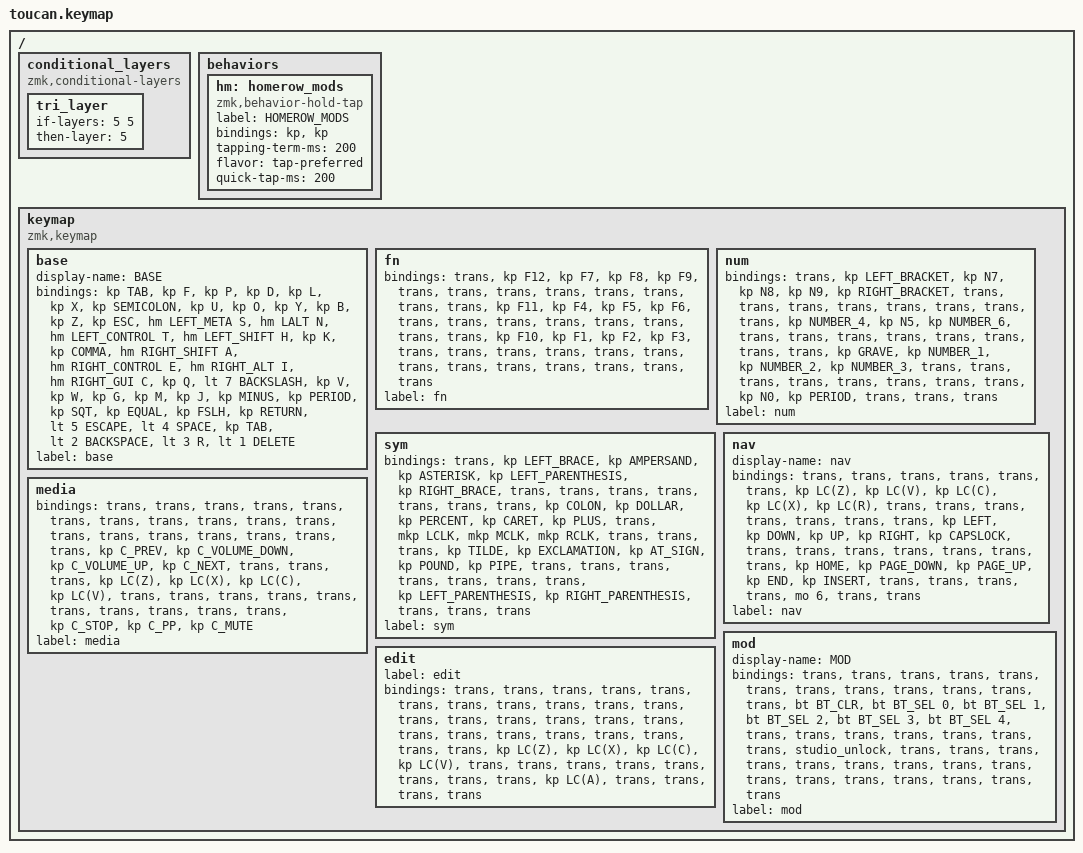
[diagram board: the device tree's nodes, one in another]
#include <behaviors.dtsi>
#include <dt-bindings/zmk/bt.h>
#include <dt-bindings/zmk/keys.h>
#include <dt-bindings/zmk/pointing.h>

#define BASE 0
#define NAV  1
#define SYM  2
#define ADJ  3

/ {
    conditional_layers {
        compatible = "zmk,conditional-layers";

        tri_layer {
            if-layers = <5 5>;
            then-layer = <5>;
        };
    };

    behaviors {
        hm: homerow_mods {
            compatible = "zmk,behavior-hold-tap";
            label = "HOMEROW_MODS";
            #binding-cells = <2>;
            bindings = <&kp>, <&kp>;

            tapping-term-ms = <200>;
            flavor = "tap-preferred";
            quick-tap-ms = <200>;
        };
    };

    keymap {
        compatible = "zmk,keymap";

        base {
            display-name = "BASE";
            bindings = <
&kp TAB  &kp F  &kp P  &kp D  &kp L  &kp X  &kp SEMICOLON  &kp U  &kp O  &kp Y  &kp B  &kp Z  &kp ESC  &hm LEFT_META S  &hm LALT N  &hm LEFT_CONTROL T  &hm LEFT_SHIFT H  &kp K  &kp COMMA  &hm RIGHT_SHIFT A  &hm RIGHT_CONTROL E  &hm RIGHT_ALT I  &hm RIGHT_GUI C  &kp Q  &lt 7 BACKSLASH  &kp V  &kp W  &kp G  &kp M  &kp J  &kp MINUS  &kp PERIOD  &kp SQT  &kp EQUAL  &kp FSLH  &kp RETURN  &lt 5 ESCAPE  &lt 4 SPACE  &kp TAB  &lt 2 BACKSPACE  &lt 3 R  &lt 1 DELETE
            >;

            label = "base";
        };

        fn {
            bindings = <
&trans  &kp F12  &kp F7  &kp F8  &kp F9  &trans  &trans  &trans  &trans  &trans  &trans  &trans  &trans  &kp F11  &kp F4  &kp F5  &kp F6  &trans  &trans  &trans  &trans  &trans  &trans  &trans  &trans  &kp F10  &kp F1  &kp F2  &kp F3  &trans  &trans  &trans  &trans  &trans  &trans  &trans  &trans  &trans  &trans  &trans  &trans  &trans
            >;

            label = "fn";
        };

        num {
            bindings = <
&trans  &kp LEFT_BRACKET  &kp N7  &kp N8  &kp N9  &kp RIGHT_BRACKET  &trans  &trans  &trans  &trans  &trans  &trans  &trans  &trans  &kp NUMBER_4  &kp N5  &kp NUMBER_6  &trans  &trans  &trans  &trans  &trans  &trans  &trans  &trans  &kp GRAVE  &kp NUMBER_1  &kp NUMBER_2  &kp NUMBER_3  &trans  &trans  &trans  &trans  &trans  &trans  &trans  &trans  &kp N0  &kp PERIOD  &trans  &trans  &trans
            >;

            label = "num";
        };

        sym {
            bindings = <
&trans  &kp LEFT_BRACE  &kp AMPERSAND  &kp ASTERISK  &kp LEFT_PARENTHESIS  &kp RIGHT_BRACE  &trans  &trans  &trans  &trans  &trans  &trans  &trans  &kp COLON  &kp DOLLAR  &kp PERCENT  &kp CARET  &kp PLUS  &trans  &mkp LCLK  &mkp MCLK  &mkp RCLK  &trans  &trans  &trans  &kp TILDE  &kp EXCLAMATION  &kp AT_SIGN  &kp POUND  &kp PIPE  &trans  &trans  &trans  &trans  &trans  &trans  &trans  &kp LEFT_PARENTHESIS  &kp RIGHT_PARENTHESIS  &trans  &trans  &trans
            >;

            label = "sym";
        };

        nav {
            display-name = "nav";
            bindings = <
&trans  &trans  &trans  &trans  &trans  &trans  &kp LC(Z)  &kp LC(V)  &kp LC(C)  &kp LC(X)  &kp LC(R)  &trans  &trans  &trans  &trans  &trans  &trans  &trans  &kp LEFT  &kp DOWN  &kp UP  &kp RIGHT  &kp CAPSLOCK  &trans  &trans  &trans  &trans  &trans  &trans  &trans  &kp HOME  &kp PAGE_DOWN  &kp PAGE_UP  &kp END  &kp INSERT  &trans  &trans  &trans  &trans  &mo 6  &trans  &trans
            >;

            label = "nav";
        };

        media {
            bindings = <
&trans  &trans  &trans  &trans  &trans  &trans  &trans  &trans  &trans  &trans  &trans  &trans  &trans  &trans  &trans  &trans  &trans  &trans  &kp C_PREV  &kp C_VOLUME_DOWN  &kp C_VOLUME_UP  &kp C_NEXT  &trans  &trans  &trans  &kp LC(Z)  &kp LC(X)  &kp LC(C)  &kp LC(V)  &trans  &trans  &trans  &trans  &trans  &trans  &trans  &trans  &trans  &trans  &kp C_STOP  &kp C_PP  &kp C_MUTE
            >;

            label = "media";
        };

        mod {
            display-name = "MOD";
            bindings = <
&trans  &trans  &trans  &trans  &trans  &trans  &trans  &trans  &trans  &trans  &trans  &trans  &bt BT_CLR  &bt BT_SEL 0  &bt BT_SEL 1  &bt BT_SEL 2  &bt BT_SEL 3  &bt BT_SEL 4  &trans  &trans  &trans  &trans  &trans  &trans  &trans  &studio_unlock  &trans  &trans  &trans  &trans  &trans  &trans  &trans  &trans  &trans  &trans  &trans  &trans  &trans  &trans  &trans  &trans
            >;

            label = "mod";
        };

        edit {
            label = "edit";
            bindings = <
&trans  &trans  &trans  &trans  &trans  &trans  &trans  &trans  &trans  &trans  &trans  &trans  &trans  &trans  &trans  &trans  &trans  &trans  &trans  &trans  &trans  &trans  &trans  &trans  &trans  &kp LC(Z)  &kp LC(X)  &kp LC(C)  &kp LC(V)  &trans  &trans  &trans  &trans  &trans  &trans  &trans  &trans  &kp LC(A)  &trans  &trans  &trans  &trans
            >;
        };
    };
};
